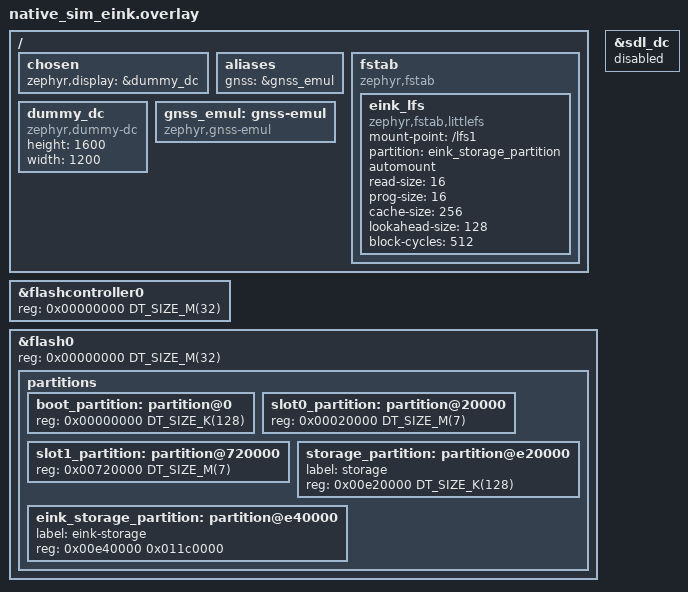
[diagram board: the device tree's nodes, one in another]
/*
 * Headless e-ink simulator: dummy display at EL133UF1 geometry.
 * For SDL (optional), use native_sim_eink_sdl.overlay + CONFIG_SDL_DISPLAY=y.
 *
 * Model the proposed custom RT1170 board's 32 MiB XIP NOR:
 *   128 KiB MCUboot, 7 MiB slot A, 7 MiB slot B,
 *   128 KiB Mender NVS, and the remaining 17.75 MiB for e-ink LittleFS.
 */
/delete-node/ &boot_partition;
/delete-node/ &slot0_partition;
/delete-node/ &slot1_partition;
/delete-node/ &scratch_partition;
/delete-node/ &storage_partition;

/ {
	chosen {
		zephyr,display = &dummy_dc;
	};

	aliases {
		gnss = &gnss_emul;
	};

	fstab {
		compatible = "zephyr,fstab";

		eink_lfs: eink_lfs {
			compatible = "zephyr,fstab,littlefs";
			mount-point = "/lfs1";
			partition = <&eink_storage_partition>;
			automount;
			read-size = <16>;
			prog-size = <16>;
			cache-size = <256>;
			lookahead-size = <128>;
			block-cycles = <512>;
		};
	};

	dummy_dc: dummy_dc {
		compatible = "zephyr,dummy-dc";
		height = <1600>;
		width = <1200>;
	};

	/* Zephyr GNSS emulator — feeds APP_EINK_GNSS → eink_location. */
	gnss_emul: gnss-emul {
		compatible = "zephyr,gnss-emul";
		status = "okay";
	};
};

&flashcontroller0 {
	reg = <0x00000000 DT_SIZE_M(32)>;
};

&flash0 {
	reg = <0x00000000 DT_SIZE_M(32)>;

	partitions {
		boot_partition: partition@0 {
			reg = <0x00000000 DT_SIZE_K(128)>;
		};

		slot0_partition: partition@20000 {
			reg = <0x00020000 DT_SIZE_M(7)>;
		};

		slot1_partition: partition@720000 {
			reg = <0x00720000 DT_SIZE_M(7)>;
		};

		storage_partition: partition@e20000 {
			label = "storage";
			reg = <0x00e20000 DT_SIZE_K(128)>;
		};

		eink_storage_partition: partition@e40000 {
			label = "eink-storage";
			reg = <0x00e40000 0x011c0000>;
		};
	};
};

/* Disable SDL node so DUMMY is the only display */
&sdl_dc {
	status = "disabled";
};
